# RA register map
Vendor: Renesas; Series: All Chips; File version: x.xx
Registers are 32-bit, read-write, reset 0x0 unless marked. A register's access mark holds for its fields unless they carry their own. Offsets are from the block's base; [hi:lo] are bit positions; lines under a group give offsets from that group; {n}, {i} and the like mark numbered series; 'fields as' and 'values as' point back to an identical list; <NAME> marks a mode.

## R_FACI_HP_CMD — Flash Application Command Interface Command-Issuing Area
Base 0x407E0000
0x00 FACI_CMD16 16-bit — FACI Command Issuing Area (halfword access)
0x00 FACI_CMD8 8-bit (alternate view of FACI_CMD16) — FACI Command Issuing Area (halfword access)

## R_FCACHE — Flash Memory Cache
Base 0x4001C000
0x100 FCACHEE 16-bit — Flash Cache Enable Register
  [0] FCACHEEN — FCACHE Enable
    0=Disable FCACHE; 1=Enable FCACHE
0x104 FCACHEIV 16-bit — Flash Cache Invalidate Register
  [0] FCACHEIV
    0=Do not invalidate reads, setting ignored on writes; 1=Invalidate on reads and writes
0x11C FLWT 8-bit reset not defined — Flash Wait Cycle Register
  [2:0] FLWT — Flash Wait Cycle
    0=0 waits (ICLK <= 80 MHz); 1=1 wait (80 MHz < ICLK <= 160 MHz); 2=2 waits (160 MHz < ICLK <= 240 MHz)

## R_GPT_ODC — PWM Delay Generation Circuit
Base 0x4007B000
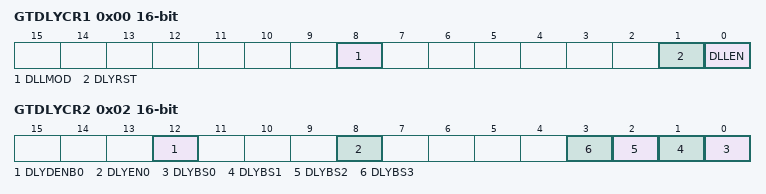
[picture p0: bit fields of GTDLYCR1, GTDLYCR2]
0x00 GTDLYCR1 16-bit — PWM Output Delay Control Register1
  [8] DLLMOD — DLL Mode Select
    0=5 bit-mode; 1=4 bit-mode
  [1] DLYRST — PWM Delay Generation Circuit Reset
    0=Normal operation; 1=Reset
  [0] DLLEN — DLL Operation Enable
    0=DLL operation is disabled; 1=DLL operation is enabled
0x02 GTDLYCR2 16-bit — PWM Output Delay Control Register2
  [n+12] DLYDENB{n} (n=0..0) — PWM Delay Generation Circuit Disenable for GTIOCB
    0=Delay generation circuit of GTIOCB is based on DLYEN1; 1=Delay generation circuit of GTIOCB is disabled
  [n+8] DLYEN{n} (n=0..0) — PWM Delay Generation Circuit enable
    0=Delay generation circuit of channel is enabled; 1=Delay generation circuit of channel is disabled
  [n] DLYBS{n} (n=0..3) — PWM Delay Generation Circuit bypass
    0=Delay generation circuit of channel is bypassed; 1=Delay generation circuit of channel is not bypassed
{0x18+4i} GTDLYR[{i}] (i=0..3) group — PWM DELAY RISING
  0x00 A 16-bit — GTIOCA Output Delay Register
    [4:0] DLY — GTIOCnA Output Rising Edge Delay Setting
      0=No delay on rising edges; other=others (Delay of DLY/32 times the PCLKD period is applied.)
  0x02 B 16-bit — GTIOCB Output Delay Register
    fields as GTDLYR[0].A
0x28 GTDLYF[%s] group — PWM DELAY FALLING
  0x00 A 16-bit — GTIOCA Output Delay Register
    fields as GTDLYR[0].A
  0x02 B 16-bit — GTIOCB Output Delay Register
    fields as GTDLYR[0].A

## R_GPT_OPS — Output Phase Switching for GPT
Base 0x40078FF0
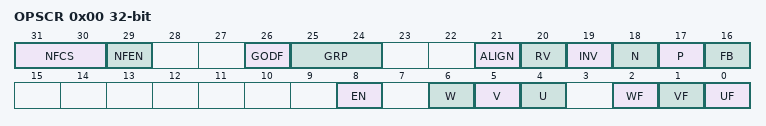
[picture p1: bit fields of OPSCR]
0x00 OPSCR — Output Phase Switching Control Register
  [31:30] NFCS — External Input Noise Filter Clock selectionNoise filter sampling clock setting of the external input.
    0=PCLK/1; 1=PCLK/4; 2=PCLK/16; 3=PCLK/64
  [29] NFEN — External Input Noise Filter Enable
    0=Do not use a noise filter to the external input; 1=Use a noise filter to the external input
  [26] GODF — Group output disable function
    0=This bit function is ignored; 1=Group disable will clear OPSCR.EN Bit
  [25:24] GRP — Output disabled source selection
    0=Select Group A output disable source; 1=Select Group B output disable source; 2=Select Group C output disable source; 3=Select Group D output disable source
  [21] ALIGN — Input phase alignment
    0=Input phase is aligned to PCLK; 1=Input phase is aligned PWM
  [20] RV — Output phase rotation direction reversal
    0=U/V/W-Phase output; 1=Output to reverse the V / W-phase
  [19] INV — Invert-Phase Output Control
    0=Positive Logic (Active High)output; 1=Negative Logic (Active Low)output
  [18] N — Negative-Phase Output (N) Control
    0=Level signal output; 1=PWM signal output (PWM of GPT0)
  [17] P — Positive-Phase Output (P) Control
    0=Level signal output; 1=PWM signal output (PWM of GPT0)
  [16] FB — External Feedback Signal EnableThis bit selects the input phase from the software settings and external input.
    0=Select the external input; 1=Select the soft setting(OPSCR.UF, VF, WF)
  [8] EN — Enable-Phase Output Control
    0=Not Output(Hi-Z external terminals); 1=Output
  [6] W ro — Input W-Phase MonitorThis bit monitors the state of the input phase.OPSCR.FB=0:External input monitoring by PCLKOPSCR.FB=1:Software settings (UF/VF/WF)
  [5] V ro — Input V-Phase MonitorThis bit monitors the state of the input phase.OPSCR.FB=0:External input monitoring by PCLKOPSCR.FB=1:Software settings (UF/VF/WF)
  [4] U ro — Input U-Phase MonitorThis bit monitors the state of the input phase.OPSCR.FB=0:External input monitoring by PCLKOPSCR.FB=1:Software settings (UF/VF/WF)
  [2] WF — Input Phase Soft Setting UFThis bit sets the input phase by the software settings.This bit setting is valid when the OPSCR.FB bit = 1.
  [1] VF — Input Phase Soft Setting VFThis bit sets the input phase by the software settings.This bit setting is valid when the OPSCR.FB bit = 1.
  [0] UF — Input Phase Soft Setting WFThis bit sets the input phase by the software settings.This bit setting is valid when the OPSCR.FB bit = 1.
